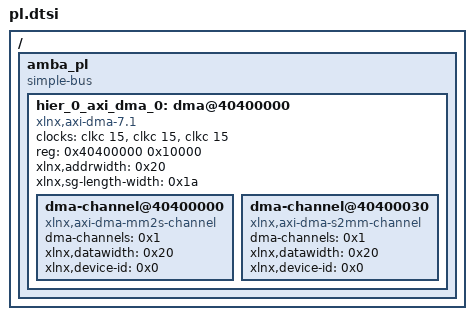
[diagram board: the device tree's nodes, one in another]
/*
 * CAUTION: This file is automatically generated by Xilinx.
 * Version: XSCT 2019.1
 * Today is: Fri Jul 14 07:55:56 2023
 */


/ {
	amba_pl: amba_pl {
		#address-cells = <1>;
		#size-cells = <1>;
		compatible = "simple-bus";
		ranges ;
		hier_0_axi_dma_0: dma@40400000 {
			#dma-cells = <1>;
			clock-names = "s_axi_lite_aclk", "m_axi_mm2s_aclk", "m_axi_s2mm_aclk";
			clocks = <&clkc 15>, <&clkc 15>, <&clkc 15>;
			compatible = "xlnx,axi-dma-7.1", "xlnx,axi-dma-1.00.a";
			reg = <0x40400000 0x10000>;
			xlnx,addrwidth = <0x20>;
			xlnx,sg-length-width = <0x1a>;
			dma-channel@40400000 {
				compatible = "xlnx,axi-dma-mm2s-channel";
				dma-channels = <0x1>;
				xlnx,datawidth = <0x20>;
				xlnx,device-id = <0x0>;
			};
			dma-channel@40400030 {
				compatible = "xlnx,axi-dma-s2mm-channel";
				dma-channels = <0x1>;
				xlnx,datawidth = <0x20>;
				xlnx,device-id = <0x0>;
			};
		};
	};
};
